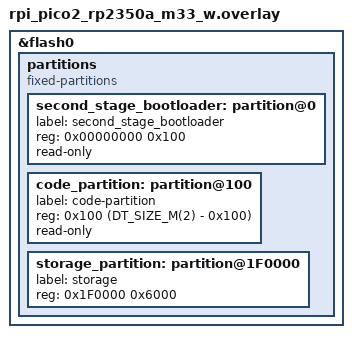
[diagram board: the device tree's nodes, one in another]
#include <zephyr/dt-bindings/pwm/pwm.h>
#include <zephyr/dt-bindings/led/led.h>
/*
&wifi {
        status = "okay";
};
*/

&flash0 {
	status = "okay";
	partitions {
        compatible = "fixed-partitions";
	    #address-cells = < 0x1 >;
		#size-cells = < 0x1 >;
		/* Reserved memory for the second stage bootloader */
		second_stage_bootloader: partition@0 {
			label = "second_stage_bootloader";
			reg = <0x00000000 0x100>;
			read-only;
		};

		/*
		 * Usable flash. Starts at 0x100, after the bootloader. The partition
		 * size is 2MB minus the 0x100 bytes taken by the bootloader.
		 */
		code_partition: partition@100 {
			label = "code-partition";
			reg = <0x100 (DT_SIZE_M(2) - 0x100)>;
			read-only;
		};
		storage_partition: partition@1F0000 {
			label = "storage";
			reg = < 0x1F0000 0x6000 >;
		};
    };
};
